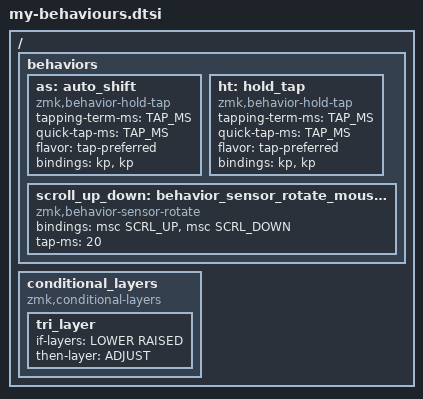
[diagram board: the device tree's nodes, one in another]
/ {
    behaviors {
        as: auto_shift {
                compatible = "zmk,behavior-hold-tap";
                #binding-cells = <2>;
                tapping-term-ms = <TAP_MS>;
                quick-tap-ms = <TAP_MS>;
                flavor = "tap-preferred";
                bindings = <&kp>, <&kp>;
            };

        ht: hold_tap {
                compatible = "zmk,behavior-hold-tap";
                #binding-cells = <2>;
                tapping-term-ms = <TAP_MS>;
                quick-tap-ms = <TAP_MS>;
                flavor = "tap-preferred";
                bindings = <&kp>, <&kp>;
            };
        scroll_up_down: behavior_sensor_rotate_mouse_scroll {
            compatible = "zmk,behavior-sensor-rotate";
            #sensor-binding-cells = <0>;
            bindings = <&msc SCRL_UP>, <&msc SCRL_DOWN>;
            tap-ms = <20>; // Optional: increases scroll signal duration
        };
    };

    conditional_layers {
        compatible = "zmk,conditional-layers";
        tri_layer {
            if-layers = <LOWER RAISED>;
            then-layer = <ADJUST>;
        };
    };

};
